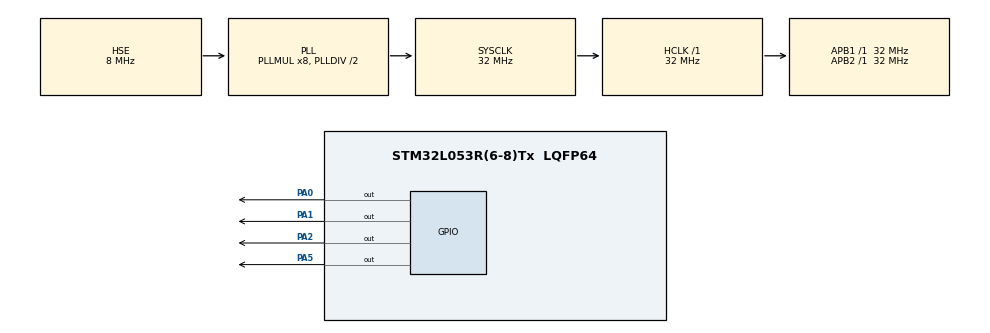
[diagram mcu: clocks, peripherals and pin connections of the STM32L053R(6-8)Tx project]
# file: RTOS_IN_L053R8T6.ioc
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FREERTOS.Tasks01=defaultTask,0,128,StartDefaultTask,Default,NULL,Dynamic,NULL,NULL;myTask02,0,128,StartTask02,Default,NULL,Dynamic,NULL,NULL;myTask03,0,128,StartTask03,Default,NULL,Dynamic,NULL,NULL
FREERTOS.configUSE_NEWLIB_REENTRANT=1
Mcu.Family=STM32L0
Mcu.Name=STM32L053R(6-8)Tx
Mcu.Package=LQFP64
NVIC.TIM2_IRQn=true\:3\:0\:false\:false\:true\:false\:false\:true\:true
NVIC.TimeBase=TIM2_IRQn
NVIC.TimeBaseIP=TIM2
PA0.Signal=GPIO_Output
PA1.Signal=GPIO_Output
PA13.Mode=Serial_Wire
PA13.Signal=SYS_SWDIO
PA14.Mode=Serial_Wire
PA14.Signal=SYS_SWCLK
PA2.Signal=GPIO_Output
PA5.Signal=GPIO_Output
PH0-OSC_IN.Mode=HSE-External-Oscillator
PH0-OSC_IN.Signal=RCC_OSC_IN
PH1-OSC_OUT.Mode=HSE-External-Oscillator
PH1-OSC_OUT.Signal=RCC_OSC_OUT
ProjectManager.HeapSize=0x200
ProjectManager.StackSize=0x400
ProjectManager.TargetToolchain=STM32CubeIDE
RCC.AHBFreq_Value=32000000
RCC.APB1Freq_Value=32000000
RCC.APB1TimFreq_Value=32000000
RCC.APB2Freq_Value=32000000
RCC.APB2TimFreq_Value=32000000
RCC.HCLKFreq_Value=32000000
RCC.HSE_VALUE=8000000
RCC.HSI16_VALUE=16000000
RCC.HSI48_VALUE=48000000
RCC.HSI_VALUE=16000000
RCC.LSE_VALUE=32768
RCC.MSI_VALUE=2097000
RCC.PLLMUL=RCC_PLLMUL_8
RCC.PLLSourceVirtual=RCC_PLLSOURCE_HSE
RCC.SYSCLKFreq_VALUE=32000000
RCC.SYSCLKSource=RCC_SYSCLKSOURCE_PLLCLK
RCC.VCOOutputFreq_Value=64000000
VP_FREERTOS_VS_CMSIS_V1.Mode=CMSIS_V1
VP_SYS_VS_tim2.Mode=TIM2
board=custom

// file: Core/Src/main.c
/* USER CODE BEGIN Header */
/**
  ******************************************************************************
  * @file           : main.c
  * @brief          : Main program body
  ******************************************************************************
  * @attention
  *
  * Copyright (c) 2023 STMicroelectronics.
  * All rights reserved.
  *
  * This software is licensed under terms that can be found in the LICENSE file
  * in the root directory of this software component.
  * If no LICENSE file comes with this software, it is provided AS-IS.
  *
  ******************************************************************************
  */
/* USER CODE END Header */
#include "main.h"
#include "cmsis_os.h"

osThreadId defaultTaskHandle;
osThreadId myTask02Handle;
osThreadId myTask03Handle;

void SystemClock_Config(void);
static void MX_GPIO_Init(void);
void StartDefaultTask(void const * argument);
void StartTask02(void const * argument);
void StartTask03(void const * argument);

int main(void)
{

  /* MCU Configuration--------------------------------------------------------*/

  /* Reset of all peripherals, Initializes the Flash interface and the Systick. */
  HAL_Init();

  /* Configure the system clock */
  SystemClock_Config();

  /* Initialize all configured peripherals */
  MX_GPIO_Init();

  /* Create the thread(s) */
  /* definition and creation of defaultTask */
  osThreadDef(defaultTask, StartDefaultTask, osPriorityNormal, 0, 128);
  defaultTaskHandle = osThreadCreate(osThread(defaultTask), NULL);

  /* definition and creation of myTask02 */
  osThreadDef(myTask02, StartTask02, osPriorityNormal, 0, 128);
  myTask02Handle = osThreadCreate(osThread(myTask02), NULL);

  /* definition and creation of myTask03 */
  osThreadDef(myTask03, StartTask03, osPriorityNormal, 0, 128);
  myTask03Handle = osThreadCreate(osThread(myTask03), NULL);

  /* Start scheduler */
  osKernelStart();

  /* We should never get here as control is now taken by the scheduler */
  /* Infinite loop */
  while (1)
  {

  }
}

void SystemClock_Config(void)
{
  RCC_OscInitTypeDef RCC_OscInitStruct = {0};
  RCC_ClkInitTypeDef RCC_ClkInitStruct = {0};

  /** Configure the main internal regulator output voltage
  */
  __HAL_PWR_VOLTAGESCALING_CONFIG(PWR_REGULATOR_VOLTAGE_SCALE1);

  /** Initializes the RCC Oscillators according to the specified parameters
  * in the RCC_OscInitTypeDef structure.
  */
  RCC_OscInitStruct.OscillatorType = RCC_OSCILLATORTYPE_HSE;
  RCC_OscInitStruct.HSEState = RCC_HSE_ON;
  RCC_OscInitStruct.PLL.PLLState = RCC_PLL_ON;
  RCC_OscInitStruct.PLL.PLLSource = RCC_PLLSOURCE_HSE;
  RCC_OscInitStruct.PLL.PLLMUL = RCC_PLLMUL_8;
  RCC_OscInitStruct.PLL.PLLDIV = RCC_PLLDIV_2;
  if (HAL_RCC_OscConfig(&RCC_OscInitStruct) != HAL_OK)
  {
    Error_Handler();
  }

  /** Initializes the CPU, AHB and APB buses clocks
  */
  RCC_ClkInitStruct.ClockType = RCC_CLOCKTYPE_HCLK|RCC_CLOCKTYPE_SYSCLK
                              |RCC_CLOCKTYPE_PCLK1|RCC_CLOCKTYPE_PCLK2;
  RCC_ClkInitStruct.SYSCLKSource = RCC_SYSCLKSOURCE_PLLCLK;
  RCC_ClkInitStruct.AHBCLKDivider = RCC_SYSCLK_DIV1;
  RCC_ClkInitStruct.APB1CLKDivider = RCC_HCLK_DIV1;
  RCC_ClkInitStruct.APB2CLKDivider = RCC_HCLK_DIV1;

  if (HAL_RCC_ClockConfig(&RCC_ClkInitStruct, FLASH_LATENCY_1) != HAL_OK)
  {
    Error_Handler();
  }
}

static void MX_GPIO_Init(void)
{
  GPIO_InitTypeDef GPIO_InitStruct = {0};

  /* GPIO Ports Clock Enable */
  __HAL_RCC_GPIOH_CLK_ENABLE();
  __HAL_RCC_GPIOA_CLK_ENABLE();

  /*Configure GPIO pin Output Level */
  HAL_GPIO_WritePin(GPIOA, GPIO_PIN_0|GPIO_PIN_1|GPIO_PIN_2|GPIO_PIN_5, GPIO_PIN_RESET);

  /*Configure GPIO pins : PA0 PA1 PA2 PA5 */
  GPIO_InitStruct.Pin = GPIO_PIN_0|GPIO_PIN_1|GPIO_PIN_2|GPIO_PIN_5;
  GPIO_InitStruct.Mode = GPIO_MODE_OUTPUT_PP;
  GPIO_InitStruct.Pull = GPIO_NOPULL;
  GPIO_InitStruct.Speed = GPIO_SPEED_FREQ_LOW;
  HAL_GPIO_Init(GPIOA, &GPIO_InitStruct);

}

void StartDefaultTask(void const * argument)
{
  /* USER CODE BEGIN 5 */
  /* Infinite loop */
  for(;;)
  {
	  HAL_GPIO_TogglePin(GPIOA, GPIO_PIN_2);
	      osDelay(1000);
  }
  /* USER CODE END 5 */
}

void StartTask02(void const * argument)
{
  /* USER CODE BEGIN StartTask02 */
  /* Infinite loop */
  for(;;)
  {
	  HAL_GPIO_TogglePin(GPIOA, GPIO_PIN_1);
    osDelay(2000);
  }
  /* USER CODE END StartTask02 */
}

void StartTask03(void const * argument)
{
  /* USER CODE BEGIN StartTask03 */
  /* Infinite loop */
  for(;;)
  {
	  HAL_GPIO_TogglePin(GPIOA, GPIO_PIN_5);
	      osDelay(3000);
  }
  /* USER CODE END StartTask03 */
}

void HAL_TIM_PeriodElapsedCallback(TIM_HandleTypeDef *htim)
{
  if (htim->Instance == TIM2) {
    HAL_IncTick();
  }
}

void Error_Handler(void)
{
  __disable_irq();
  while (1)
  {
  }
}
